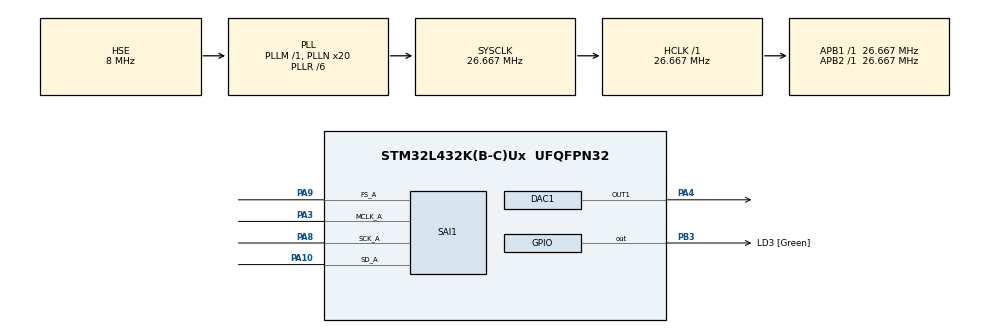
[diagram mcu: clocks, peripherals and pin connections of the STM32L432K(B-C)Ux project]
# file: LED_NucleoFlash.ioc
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DAC1.DAC_SampleAndHold-DAC_OUT1=DAC_SAMPLEANDHOLD_DISABLE
DAC1.DAC_Trigger-DAC_OUT1=DAC_TRIGGER_T2_TRGO
Dma.DAC_CH1.0.Direction=DMA_MEMORY_TO_PERIPH
Dma.DAC_CH1.0.Instance=DMA1_Channel3
Dma.DAC_CH1.0.MemDataAlignment=DMA_MDATAALIGN_WORD
Dma.DAC_CH1.0.MemInc=DMA_MINC_ENABLE
Dma.DAC_CH1.0.Mode=DMA_CIRCULAR
Dma.DAC_CH1.0.PeriphDataAlignment=DMA_PDATAALIGN_WORD
Dma.DAC_CH1.0.PeriphInc=DMA_PINC_DISABLE
Dma.DAC_CH1.0.Priority=DMA_PRIORITY_HIGH
Dma.Request0=DAC_CH1
Dma.Request1=SAI1_A
Dma.SAI1_A.1.Direction=DMA_MEMORY_TO_PERIPH
Dma.SAI1_A.1.Instance=DMA2_Channel1
Dma.SAI1_A.1.MemDataAlignment=DMA_MDATAALIGN_HALFWORD
Dma.SAI1_A.1.MemInc=DMA_MINC_ENABLE
Dma.SAI1_A.1.Mode=DMA_CIRCULAR
Dma.SAI1_A.1.PeriphDataAlignment=DMA_PDATAALIGN_HALFWORD
Dma.SAI1_A.1.PeriphInc=DMA_PINC_DISABLE
Dma.SAI1_A.1.Priority=DMA_PRIORITY_LOW
Mcu.Family=STM32L4
Mcu.Name=STM32L432K(B-C)Ux
Mcu.Package=UFQFPN32
NVIC.DMA1_Channel3_IRQn=true\:0\:0\:false\:false\:true\:false\:true\:true
NVIC.DMA2_Channel1_IRQn=true\:0\:0\:false\:false\:true\:false\:true\:true
NVIC.PriorityGroup=NVIC_PRIORITYGROUP_4
PA0.GPIO_Label=MCO [High speed clock in]
PA0.Mode=HSE-External-Clock-Source-for-LittleOrca
PA0.Signal=RCC_CK_IN
PA10.Mode=SAI_A_MasterWithClock
PA10.Signal=SAI1_SD_A
PA13\ (JTMS-SWDIO).GPIO_Label=SWDIO
PA13\ (JTMS-SWDIO).Mode=Serial_Wire
PA13\ (JTMS-SWDIO).Signal=SYS_JTMS-SWDIO
PA14\ (JTCK-SWCLK).GPIO_Label=SWCLK
PA14\ (JTCK-SWCLK).Mode=Serial_Wire
PA14\ (JTCK-SWCLK).Signal=SYS_JTCK-SWCLK
PA15\ (JTDI).GPIO_Label=VCP_RX
PA15\ (JTDI).Signal=USART2_RX
PA2.GPIO_Label=VCP_TX
PA2.Signal=USART2_TX
PA3.Mode=SAI_A_MasterWithClock
PA3.Signal=SAI1_MCLK_A
PA4.Signal=COMP_DAC11_group
PA8.Mode=SAI_A_MasterWithClock
PA8.Signal=SAI1_SCK_A
PA9.Mode=SAI_A_MasterWithClock
PA9.Signal=SAI1_FS_A
PB3\ (JTDO-TRACESWO).GPIO_Label=LD3 [Green]
PB3\ (JTDO-TRACESWO).Signal=GPIO_Output
PC14-OSC32_IN\ (PC14).Mode=LSE-External-Oscillator
PC14-OSC32_IN\ (PC14).Signal=RCC_OSC32_IN
PC15-OSC32_OUT\ (PC15).Mode=LSE-External-Oscillator
PC15-OSC32_OUT\ (PC15).Signal=RCC_OSC32_OUT
ProjectManager.HeapSize=0x200
ProjectManager.StackSize=0x400
ProjectManager.TargetToolchain=STM32CubeIDE
RCC.ADCFreq_Value=144000000
RCC.AHBFreq_Value=26666666.666666668
RCC.APB1Freq_Value=26666666.666666668
RCC.APB1TimFreq_Value=26666666.666666668
RCC.APB2Freq_Value=26666666.666666668
RCC.APB2TimFreq_Value=26666666.666666668
RCC.CortexFreq_Value=26666666.666666668
RCC.HCLKFreq_Value=26666666.666666668
RCC.HSE_VALUE=8000000
RCC.HSI16_VALUE=16000000
RCC.HSI48_VALUE=48000000
RCC.HSI_VALUE=16000000
RCC.MSIClockRange=RCC_MSIRANGE_10
RCC.MSI_VALUE=32000000
RCC.PLLMUL=RCC_PLLMUL_4
RCC.PLLN=20
RCC.PLLR=RCC_PLLR_DIV6
RCC.PLLSAI1N=36
RCC.PLLSAI1P=RCC_PLLP_DIV4
RCC.PLLSourceVirtual=RCC_PLLSOURCE_HSE
RCC.SYSCLKFreq_VALUE=26666666.666666668
RCC.SYSCLKSource=RCC_SYSCLKSOURCE_PLLCLK
RCC.USBFreq_Value=144000000
RCC.VCOOutputFreq_Value=160000000
SAI1.AudioFrequency-SAI_A_MasterWithClock=SAI_AUDIO_FREQUENCY_48K
SAI1.ErrorAudioFreq-SAI_A_MasterWithClock=-2.34 %
SAI1.InitProtocol-SAI_A_MasterWithClock=Enable
SAI1.Instance-SAI_A_MasterWithClock=SAI$Index_Block_A
SAI1.MClockEnable-SAI_A_MasterWithClock=SAI_MASTERCLOCK_ENABLE
SAI1.MonoStereoMode-SAI_A_MasterWithClock=SAI_STEREOMODE
SAI1.RealAudioFreq-SAI_A_MasterWithClock=46.875 KHz
SAI1.VirtualMode-SAI_A_MasterWithClock=VM_MASTER
SAI1.VirtualProtocol-SAI_A_BASIC=VM_BASIC_PROTOCOL
SH.COMP_DAC11_group.0=DAC1_OUT1,DAC_OUT1
TIM1.Period=624
TIM2.Period=125
TIM2.TIM_MasterOutputTrigger=TIM_TRGO_UPDATE
VP_SAI1_VP_$IpInstance_SAIA_SAI_BASIC.Mode=SAI_A_BASIC
VP_TIM1_VS_ClockSourceINT.Mode=Internal
VP_TIM2_VS_ClockSourceINT.Mode=Internal
board=NUCLEO-L432KC

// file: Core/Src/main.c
/* USER CODE BEGIN Header */
/**
  ******************************************************************************
  * @file           : main.c
  * @brief          : Main program body
  ******************************************************************************
  * @attention
  *
  * Copyright (c) 2023 STMicroelectronics.
  * All rights reserved.
  *
  * This software is licensed under terms that can be found in the LICENSE file
  * in the root directory of this software component.
  * If no LICENSE file comes with this software, it is provided AS-IS.
  *
  ******************************************************************************
  */
/* USER CODE END Header */
#include "main.h"

DAC_HandleTypeDef hdac1;
DMA_HandleTypeDef hdma_dac_ch1;

SAI_HandleTypeDef hsai_BlockA1;
DMA_HandleTypeDef hdma_sai1_a;

TIM_HandleTypeDef htim1;
TIM_HandleTypeDef htim2;

void SystemClock_Config(void);
static void MX_GPIO_Init(void);
static void MX_DMA_Init(void);
static void MX_DAC1_Init(void);
static void MX_TIM2_Init(void);
static void MX_SAI1_Init(void);
static void MX_TIM1_Init(void);
/* USER CODE BEGIN PFP */
void app_setup(void);
void app_loop(void);
/* USER CODE END PFP */

int main(void)
{

  /* MCU Configuration--------------------------------------------------------*/

  /* Reset of all peripherals, Initializes the Flash interface and the Systick. */
  HAL_Init();

  /* Configure the system clock */
  SystemClock_Config();

  /* Initialize all configured peripherals */
  MX_GPIO_Init();
  MX_DMA_Init();
  MX_DAC1_Init();
  MX_TIM2_Init();
  MX_SAI1_Init();
  MX_TIM1_Init();
  /* USER CODE BEGIN 2 */

  //Looking for something? Check app\app_main.c
  //Check https://www.e-tinkers.com/2022/04/a-better-way-to-setup-stm32cubeide/ for the setup

  app_setup();

  /* USER CODE END 2 */

  /* Infinite loop */
  while (1)
  {

    /* USER CODE BEGIN 3 */
    app_loop();
  }
  /* USER CODE END 3 */
}

void SystemClock_Config(void)
{
  RCC_OscInitTypeDef RCC_OscInitStruct = {0};
  RCC_ClkInitTypeDef RCC_ClkInitStruct = {0};

  /** Configure the main internal regulator output voltage
  */
  if (HAL_PWREx_ControlVoltageScaling(PWR_REGULATOR_VOLTAGE_SCALE1) != HAL_OK)
  {
    Error_Handler();
  }

  /** Initializes the RCC Oscillators according to the specified parameters
  * in the RCC_OscInitTypeDef structure.
  */
  RCC_OscInitStruct.OscillatorType = RCC_OSCILLATORTYPE_HSE;
  RCC_OscInitStruct.HSEState = RCC_HSE_BYPASS;
  RCC_OscInitStruct.PLL.PLLState = RCC_PLL_ON;
  RCC_OscInitStruct.PLL.PLLSource = RCC_PLLSOURCE_HSE;
  RCC_OscInitStruct.PLL.PLLM = 1;
  RCC_OscInitStruct.PLL.PLLN = 20;
  RCC_OscInitStruct.PLL.PLLP = RCC_PLLP_DIV7;
  RCC_OscInitStruct.PLL.PLLQ = RCC_PLLQ_DIV2;
  RCC_OscInitStruct.PLL.PLLR = RCC_PLLR_DIV6;
  if (HAL_RCC_OscConfig(&RCC_OscInitStruct) != HAL_OK)
  {
    Error_Handler();
  }

  /** Initializes the CPU, AHB and APB buses clocks
  */
  RCC_ClkInitStruct.ClockType = RCC_CLOCKTYPE_HCLK|RCC_CLOCKTYPE_SYSCLK
                              |RCC_CLOCKTYPE_PCLK1|RCC_CLOCKTYPE_PCLK2;
  RCC_ClkInitStruct.SYSCLKSource = RCC_SYSCLKSOURCE_PLLCLK;
  RCC_ClkInitStruct.AHBCLKDivider = RCC_SYSCLK_DIV1;
  RCC_ClkInitStruct.APB1CLKDivider = RCC_HCLK_DIV1;
  RCC_ClkInitStruct.APB2CLKDivider = RCC_HCLK_DIV1;

  if (HAL_RCC_ClockConfig(&RCC_ClkInitStruct, FLASH_LATENCY_1) != HAL_OK)
  {
    Error_Handler();
  }
}

static void MX_DAC1_Init(void)
{

  DAC_ChannelConfTypeDef sConfig = {0};

  /** DAC Initialization
  */
  hdac1.Instance = DAC1;
  if (HAL_DAC_Init(&hdac1) != HAL_OK)
  {
    Error_Handler();
  }

  /** DAC channel OUT1 config
  */
  sConfig.DAC_SampleAndHold = DAC_SAMPLEANDHOLD_DISABLE;
  sConfig.DAC_Trigger = DAC_TRIGGER_T2_TRGO;
  sConfig.DAC_OutputBuffer = DAC_OUTPUTBUFFER_ENABLE;
  sConfig.DAC_ConnectOnChipPeripheral = DAC_CHIPCONNECT_DISABLE;
  sConfig.DAC_UserTrimming = DAC_TRIMMING_FACTORY;
  if (HAL_DAC_ConfigChannel(&hdac1, &sConfig, DAC_CHANNEL_1) != HAL_OK)
  {
    Error_Handler();
  }

}

static void MX_SAI1_Init(void)
{

  hsai_BlockA1.Instance = SAI1_Block_A;
  hsai_BlockA1.Init.AudioMode = SAI_MODEMASTER_TX;
  hsai_BlockA1.Init.Synchro = SAI_ASYNCHRONOUS;
  hsai_BlockA1.Init.OutputDrive = SAI_OUTPUTDRIVE_DISABLE;
  hsai_BlockA1.Init.NoDivider = SAI_MASTERDIVIDER_ENABLE;
  hsai_BlockA1.Init.FIFOThreshold = SAI_FIFOTHRESHOLD_EMPTY;
  hsai_BlockA1.Init.AudioFrequency = SAI_AUDIO_FREQUENCY_48K;
  hsai_BlockA1.Init.SynchroExt = SAI_SYNCEXT_DISABLE;
  hsai_BlockA1.Init.MonoStereoMode = SAI_STEREOMODE;
  hsai_BlockA1.Init.CompandingMode = SAI_NOCOMPANDING;
  hsai_BlockA1.Init.TriState = SAI_OUTPUT_NOTRELEASED;
  if (HAL_SAI_InitProtocol(&hsai_BlockA1, SAI_I2S_STANDARD, SAI_PROTOCOL_DATASIZE_16BIT, 2) != HAL_OK)
  {
    Error_Handler();
  }

}

static void MX_TIM1_Init(void)
{

  TIM_ClockConfigTypeDef sClockSourceConfig = {0};
  TIM_MasterConfigTypeDef sMasterConfig = {0};

  htim1.Instance = TIM1;
  htim1.Init.Prescaler = 0;
  htim1.Init.CounterMode = TIM_COUNTERMODE_UP;
  htim1.Init.Period = 624;
  htim1.Init.ClockDivision = TIM_CLOCKDIVISION_DIV1;
  htim1.Init.RepetitionCounter = 0;
  htim1.Init.AutoReloadPreload = TIM_AUTORELOAD_PRELOAD_DISABLE;
  if (HAL_TIM_Base_Init(&htim1) != HAL_OK)
  {
    Error_Handler();
  }
  sClockSourceConfig.ClockSource = TIM_CLOCKSOURCE_INTERNAL;
  if (HAL_TIM_ConfigClockSource(&htim1, &sClockSourceConfig) != HAL_OK)
  {
    Error_Handler();
  }
  sMasterConfig.MasterOutputTrigger = TIM_TRGO_RESET;
  sMasterConfig.MasterOutputTrigger2 = TIM_TRGO2_RESET;
  sMasterConfig.MasterSlaveMode = TIM_MASTERSLAVEMODE_DISABLE;
  if (HAL_TIMEx_MasterConfigSynchronization(&htim1, &sMasterConfig) != HAL_OK)
  {
    Error_Handler();
  }

}

static void MX_TIM2_Init(void)
{

  TIM_ClockConfigTypeDef sClockSourceConfig = {0};
  TIM_MasterConfigTypeDef sMasterConfig = {0};

  htim2.Instance = TIM2;
  htim2.Init.Prescaler = 0;
  htim2.Init.CounterMode = TIM_COUNTERMODE_UP;
  htim2.Init.Period = 125;
  htim2.Init.ClockDivision = TIM_CLOCKDIVISION_DIV1;
  htim2.Init.AutoReloadPreload = TIM_AUTORELOAD_PRELOAD_DISABLE;
  if (HAL_TIM_Base_Init(&htim2) != HAL_OK)
  {
    Error_Handler();
  }
  sClockSourceConfig.ClockSource = TIM_CLOCKSOURCE_INTERNAL;
  if (HAL_TIM_ConfigClockSource(&htim2, &sClockSourceConfig) != HAL_OK)
  {
    Error_Handler();
  }
  sMasterConfig.MasterOutputTrigger = TIM_TRGO_UPDATE;
  sMasterConfig.MasterSlaveMode = TIM_MASTERSLAVEMODE_DISABLE;
  if (HAL_TIMEx_MasterConfigSynchronization(&htim2, &sMasterConfig) != HAL_OK)
  {
    Error_Handler();
  }

}

static void MX_DMA_Init(void)
{

  /* DMA controller clock enable */
  __HAL_RCC_DMA1_CLK_ENABLE();
  __HAL_RCC_DMA2_CLK_ENABLE();

  /* DMA interrupt init */
  /* DMA1_Channel3_IRQn interrupt configuration */
  HAL_NVIC_SetPriority(DMA1_Channel3_IRQn, 0, 0);
  HAL_NVIC_EnableIRQ(DMA1_Channel3_IRQn);
  /* DMA2_Channel1_IRQn interrupt configuration */
  HAL_NVIC_SetPriority(DMA2_Channel1_IRQn, 0, 0);
  HAL_NVIC_EnableIRQ(DMA2_Channel1_IRQn);

}

static void MX_GPIO_Init(void)
{
  GPIO_InitTypeDef GPIO_InitStruct = {0};

  /* GPIO Ports Clock Enable */
  __HAL_RCC_GPIOC_CLK_ENABLE();
  __HAL_RCC_GPIOA_CLK_ENABLE();
  __HAL_RCC_GPIOB_CLK_ENABLE();

  /*Configure GPIO pin Output Level */
  HAL_GPIO_WritePin(LD3_GPIO_Port, LD3_Pin, GPIO_PIN_RESET);

  /*Configure GPIO pin : VCP_TX_Pin */
  GPIO_InitStruct.Pin = VCP_TX_Pin;
  GPIO_InitStruct.Mode = GPIO_MODE_AF_PP;
  GPIO_InitStruct.Pull = GPIO_NOPULL;
  GPIO_InitStruct.Speed = GPIO_SPEED_FREQ_VERY_HIGH;
  GPIO_InitStruct.Alternate = GPIO_AF7_USART2;
  HAL_GPIO_Init(VCP_TX_GPIO_Port, &GPIO_InitStruct);

  /*Configure GPIO pin : VCP_RX_Pin */
  GPIO_InitStruct.Pin = VCP_RX_Pin;
  GPIO_InitStruct.Mode = GPIO_MODE_AF_PP;
  GPIO_InitStruct.Pull = GPIO_NOPULL;
  GPIO_InitStruct.Speed = GPIO_SPEED_FREQ_VERY_HIGH;
  GPIO_InitStruct.Alternate = GPIO_AF3_USART2;
  HAL_GPIO_Init(VCP_RX_GPIO_Port, &GPIO_InitStruct);

  /*Configure GPIO pin : LD3_Pin */
  GPIO_InitStruct.Pin = LD3_Pin;
  GPIO_InitStruct.Mode = GPIO_MODE_OUTPUT_PP;
  GPIO_InitStruct.Pull = GPIO_NOPULL;
  GPIO_InitStruct.Speed = GPIO_SPEED_FREQ_LOW;
  HAL_GPIO_Init(LD3_GPIO_Port, &GPIO_InitStruct);

}

void Error_Handler(void)
{
  __disable_irq();
  while (1)
  {
  }
}
